# TC37X register map
File version: 1.0.0
CPU: CM4 r0p1, little endian, MPU, FPU, VTOR, 3 interrupt priority bits
Registers are 16-bit, read-write, reset 0x0 unless marked. A register's access mark holds for its fields unless they carry their own. Offsets are from the block's base; [hi:lo] are bit positions; {n}, {i} and the like mark numbered series; 'fields as' and 'values as' point back to an identical list.

## MINIMCDS — ce_minimcds
Base 0xFB718000
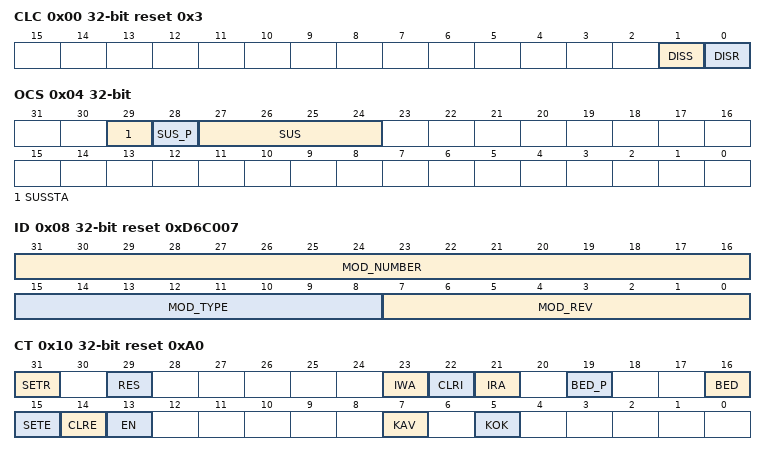
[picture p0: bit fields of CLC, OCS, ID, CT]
0x00 CLC 32-bit reset 0x3 — Clock Control Register
  [1] DISS ro — Disable Status Bit - DISS
  [0] DISR — Disable Request Bit - DISR
0x04 OCS 32-bit — OCDS Control and Status
  [29] SUSSTA ro — Suspend State(inverted busy_o) - SUSSTA
  [28] SUS_P wo — SUS Write Protection - SUS_P
  [27:24] SUS — OCDS Suspend Control - SUS
0x08 ID 32-bit ro reset 0xD6C007 — Module Identification Register
  [31:16] MOD_NUMBER — Module Number - MOD_NUMBER
  [15:8] MOD_TYPE — Module Type - MOD_TYPE
  [7:0] MOD_REV — Module Revision - MOD_REV
0x10 CT 32-bit reset 0xA0 — MCDS Control Register
  [31] SETR wo — MCDS ResetRequest Bit - SETR
  [29] RES ro — MCDS ResetFlag - RES
  [23] IWA ro — Invalid Write Access Flag - IWA
  [22] CLRI wo — Clear Invalid Access Bits - CLRI
  [21] IRA ro — Invalid Read Access Flag - IRA
  [19] BED_P wo — Bus Error Disable Protection - BED_P
  [16] BED — Bus Error Disable Flag - BED
  [15] SETE wo — Set MCDS Enable Flag - SETE
  [14] CLRE wo — Clear MCDS Enable Flag - CLRE
  [13] EN ro — MCDS Enable Flag - EN
  [7] KAV ro — Key Available Flag - KAV
  [5] KOK ro — Key OK Flag - KOK
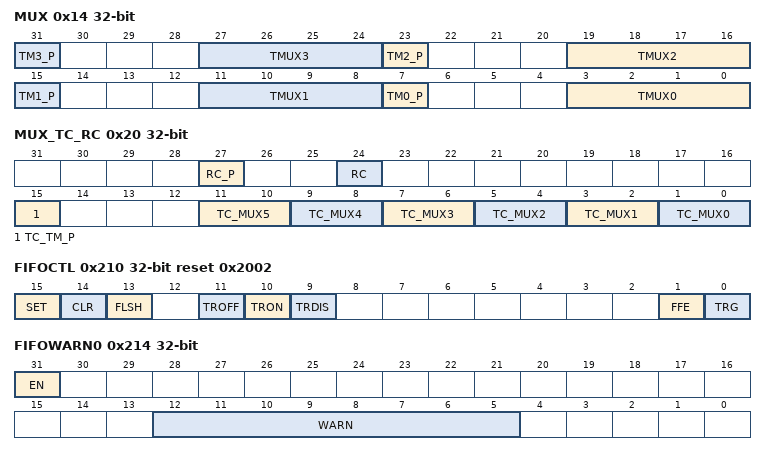
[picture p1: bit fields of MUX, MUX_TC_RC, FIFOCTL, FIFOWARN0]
0x14 MUX 32-bit — MCDS Signal Source Control
  [8n+7] TM{n}_P wo (n=0..3) — Trace Source Select {n} Protection - TM{n}_P
  [8n+3:8n] TMUX{n} (n=0..3) — Trace Source Select {n} - TMUX{n}
0x20 MUX_TC_RC 32-bit — MCDS_TC Signal Source Control
  [27] RC_P wo — Reference Clock Select Protection - RC_P
  [24] RC — Reference Clock Select - RC
  [15] TC_TM_P wo — TC_MUX Trace Source Select Protection - TC_TM_P
  [2n+1:2n] TC_MUX{n} (n=0..5) — TC_MUX Trace Source Select - TC_MUX{n}
0x200 FIFONOW 32-bit ro — Trace Buffer Write Pointer
  [12:5] NOW — Trace Buffer Current Write Pointer - NOW
0x204 FIFOBOT 32-bit — Trace Buffer Bottom Register
  [12:10] BOTTOM — Trace Buffer lower Bound - BOTTOM
0x208 FIFOPRE 32-bit — Trace Buffer PRE/POST Register
  [12:5] PRE — Trace Buffer Pre-Trigger Area Size - PRE
0x20C FIFOTOP 32-bit reset 0x1FFF — Trace Buffer Top Register
  [12:5] TOP — Trace Buffer upper Bound - TOP
0x210 FIFOCTL 32-bit reset 0x2002 — Trace Buffer Control Register
  [15] SET wo — SetFlushFlag - SET
  [14] CLR wo — ClearFlushFlag - CLR
  [13] FLSH ro — FlushFlag - FLSH
  [11] TROFF wo — SetTrigger DisableFlag - TROFF
  [10] TRON wo — ClearTrigger DisableFlag - TRON
  [9] TRDIS ro — Trigger DisableFlag - TRDIS
  [1] FFE ro — FIFO Feeder Empty - FFE
  [0] TRG ro — Trigger Received Flag - TRG
0x214 FIFOWARN0 32-bit — Trace Buffer Comparator Register
  [31] EN — Enable Trigger Generation - EN
  [12:5] WARN — Trace Buffer Warn Level - WARN
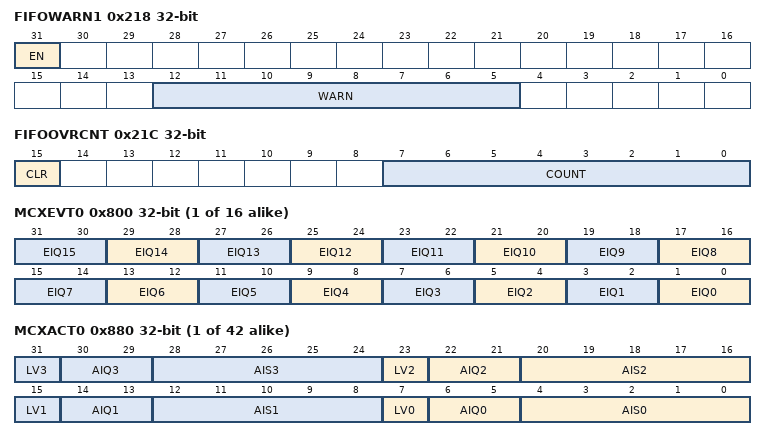
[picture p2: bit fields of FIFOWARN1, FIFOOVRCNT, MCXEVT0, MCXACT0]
0x218 FIFOWARN1 32-bit — Trace Buffer Comparator Register
  fields as FIFOWARN0
0x21C FIFOOVRCNT 32-bit — FIFO Overflow Counter Register
  [15] CLR wo — Clear counter - CLR
  [7:0] COUNT ro — FIFO Overflow Counter - COUNT
0x400 TSUREFCNT 32-bit ro — Clock Counter Register
  [31:0] COUNT — Current Count Value - COUNT
0x404 TSUPRSCL 32-bit — Clock Prescaler Register
  [31:0] RELOAD — Prescaler Reload Value - RELOAD
0x408 TSUEMUCNT 32-bit ro — Clock Counter Register
  [31:0] COUNT — Current Count Value - COUNT
{0x800+4i} MCXEVT{i} 32-bit (i=0..15) — Event Definition Register {i}
  [2n+1:2n] EIQ{n} (n=0..15) — Event Input Qualifier - EIQ{n}
{0x880+4i} MCXACT{i} 32-bit (i=0..41) — Action Definition Register {i}
  [8n+7] LV{n} (n=0..3) — Action Input Level Mode - LV{n}
  [8n+6:8n+5] AIQ{n} (n=0..3) — Action Input Qualifier - AIQ{n}
  [8n+4:8n] AIS{n} (n=0..3) — Action Input Selector - AIS{n}
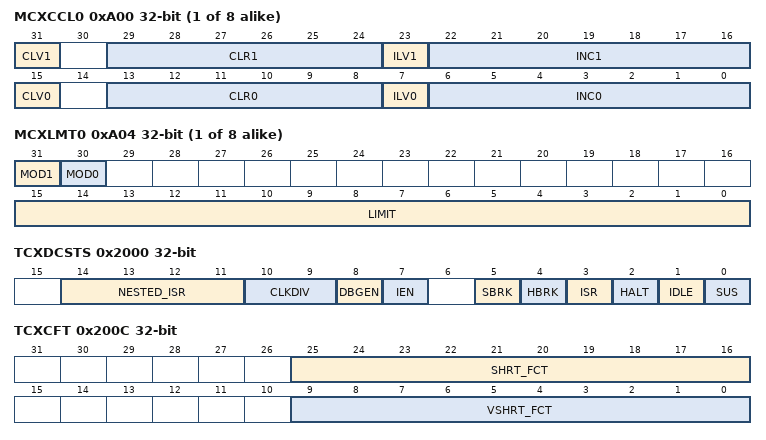
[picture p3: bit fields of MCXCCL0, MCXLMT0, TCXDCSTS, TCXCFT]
{0xA00+0x10*i} MCXCCL{i} 32-bit (i=0..7) — Counter Control Register
  [31] CLV1 — Clear Input Level Mode - CLV1
  [29:24] CLR1 — Clear Input Selector - CLR1
  [23] ILV1 — Count Input Level Mode - ILV1
  [22:16] INC1 — Count Input Selector - INC1
  [15] CLV0 — Clear Input Level Mode - CLV0
  [13:8] CLR0 — Clear Input Selector - CLR0
  [7] ILV0 — Count Input Level Mode - ILV0
  [6:0] INC0 — Count Input Selector - INC0
{0xA04+0x10*i} MCXLMT{i} 32-bit (i=0..7) — Counter Limit Register
  [31] MOD1 — Modulo Count Control - MOD1
  [30] MOD0 — Modulo Count Control - MOD0
  [15:0] LIMIT — Counter Limit - LIMIT
{0xA08+0x10*i} MCXCNT{i} 32-bit ro (i=0..7) — Current Count Register
  [15:0] COUNT — Current Counter - COUNT
0x2000 TCXDCSTS 32-bit ro — Debug Status Register
  [14:11] NESTED_ISR — Nested Interrupt Level - NESTED_ISR
  [10:9] CLKDIV — Current Clock Divider - CLKDIV
  [8] DBGEN — Debug Enabled Flag - DBGEN
  [7] IEN — Interrupt Enable Flag - IEN
  [5] SBRK — Software Break Flag - SBRK
  [4] HBRK — Hardware Break Flag - HBRK
  [3] ISR — Interrupt Service Flag - ISR
  [2] HALT — Halted Flag - HALT
  [1] IDLE — Run Flag - IDLE
  [0] SUS — Suspended Flag - SUS
0x2008 TCXCIP 32-bit ro — Current Instruction Pointer
  [31:1] CURRENT — Current Instruction Pointer - CURRENT
0x200C TCXCFT 32-bit — Compact Function Trace Register
  [25:16] SHRT_FCT — Length of short leaf function - SHRT_FCT
  [9:0] VSHRT_FCT — Length of very short leaf function - VSHRT_FCT
0x2400 TCXEABND0 32-bit — Comparator Bound Register 0
  [31:0] BOUND — Address Comparator range lower bound - BOUND
0x2404 TCXEARNG0 32-bit reset 0xFFFFFFFF — Comparator Range Register 0
  [31:0] RANGE — Address Comparator range size - RANGE
0x2410 TCXEABND1 32-bit — Comparator Bound Register 1
  [31:0] BOUND — Address Comparator range lower bound - BOUND
0x2414 TCXEARNG1 32-bit reset 0xFFFFFFFF — Comparator Range Register 1
  [31:0] RANGE — Address Comparator range size - RANGE
0x2480 TCXWDBND0 32-bit — Comparator Bound Register 0
  [31:0] BOUND — Data Comparator range lower bound - BOUND
0x2488 TCXWDRNG0 32-bit — Comparator Range Register 0
  [31:0] RANGE — Data Comparator range size - RANGE
0x2490 TCXWDMSK0 32-bit reset 0xFFFFFFFF — Comparator Mask Register 0
  [31:0] MASK — Data Comparator bit mask - MASK
0x249C TCXWDSGN0 32-bit — Comparator Sign Register 0
  [4:0] SIGN — Bit number of sign bit
0x24A0 TCXWDBND1 32-bit — Comparator Bound Register 1
  [31:0] BOUND — Data Comparator range lower bound - BOUND
0x24A8 TCXWDRNG1 32-bit — Comparator Range Register 1
  [31:0] RANGE — Data Comparator range size - RANGE
0x24B0 TCXWDMSK1 32-bit reset 0xFFFFFFFF — Comparator Mask Register 1
  [31:0] MASK — Data Comparator bit mask - MASK
0x24BC TCXWDSGN1 32-bit — Comparator Sign Register 1
  [4:0] SIGN — Bit number of sign bit
0x2500 TCXACBND0 32-bit — Comparator Bound Register 0
  [13:0] BOUND — Mode Comparator range lower bound - BOUND
0x2504 TCXACRNG0 32-bit — Comparator Range Register 0
  [13:0] RANGE — Mode Comparator range size - RANGE
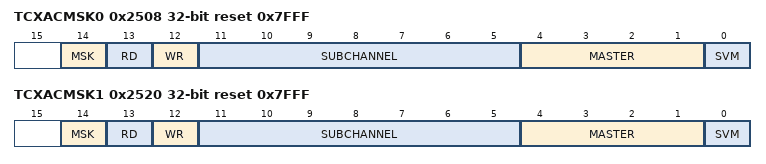
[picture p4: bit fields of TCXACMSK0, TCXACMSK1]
0x2508 TCXACMSK0 32-bit reset 0x7FFF — Comparator Mask Register 0
  [14] MSK — Bit mask for Transaction Type - MSK
  [13] RD — Comparator bit mask for Direction Read - RD
  [12] WR — Comparator bit mask for Direction Write - WR
  [11:5] SUBCHANNEL — Comparator bit mask for Sub-channel ID - SUBCHANNEL
  [4:1] MASTER — Comparator bit mask for Master ID - MASTER
  [0] SVM — Comparator bit mask for Supervisor Mode - SVM
0x2518 TCXACBND1 32-bit — Comparator Bound Register 1
  [13:0] BOUND — Mode Comparator range lower bound - BOUND
0x251C TCXACRNG1 32-bit — Comparator Range Register 1
  [13:0] RANGE — Mode Comparator range size - RANGE
0x2520 TCXACMSK1 32-bit reset 0x7FFF — Comparator Mask Register 1
  fields as TCXACMSK0
0x3000 TCXIPBND0 32-bit — Comparator Bound Register 0
  [31:1] BOUND — IP Comparator range lower bound - BOUND
0x3004 TCXIPRNG0 32-bit reset 0xFFFFFFFE — Comparator Range Register 0
  [31:1] RANGE — IP Comparator range size - RANGE
0x3010 TCXIPBND1 32-bit — Comparator Bound Register 1
  [31:1] BOUND — IP Comparator range lower bound - BOUND
0x3014 TCXIPRNG1 32-bit reset 0xFFFFFFFE — Comparator Range Register 1
  [31:1] RANGE — IP Comparator range size - RANGE
